# ATtiny20 device description
Architecture: AVR8L; Family: tinyAVR
Registers are 8-bit, access not given, no defined reset value unless marked. A register's access mark holds for its fields unless they carry their own. Offsets are from the block's base; [hi:lo] are bit positions.

## EXINT — External Interrupts
Instances: EXINT 0x00
0x09 PCMSK0 — Pin Change Mask Register 0
  [7:0] PCINT — Pin Change Enable Masks
0x0A PCMSK1 — Pin Change Mask Register 1
  [3:0] PCINT (bit 8 of the value upward) — Pin Change Enable Masks
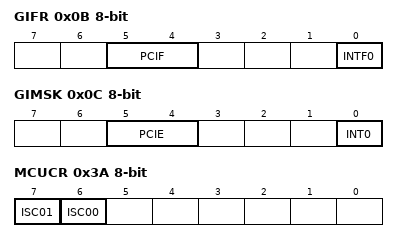
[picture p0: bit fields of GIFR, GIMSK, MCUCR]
0x0B GIFR — General Interrupt Flag Register
  [5:4] PCIF — Pin Change Interrupt Flags
  [0] INTF0 — External Interrupt Flag 0
0x0C GIMSK — General Interrupt Mask Register
  [5:4] PCIE — Pin Change Interrupt Enables
  [0] INT0 — External Interrupt Request 0 Enable
0x3A MCUCR — MCU Control Register
  [7] ISC01 — Interrupt Sense Control 0 Bit 1
  [6] ISC00 — Interrupt Sense Control 0 Bit 0
    0=Low Level of INTX; 1=Any logical change on INTX; 2=Falling Edge of INTX; 3=Rising Edge of INTX

## TC0 (TC8 module) — Timer/Counter, 8-bit
Instances: TC0 0x00
0x15 OCR0B — Timer/Counter0 Output Compare Register
0x16 OCR0A — Timer/Counter0 Output Compare Register
0x17 TCNT0 — Timer/Counter0
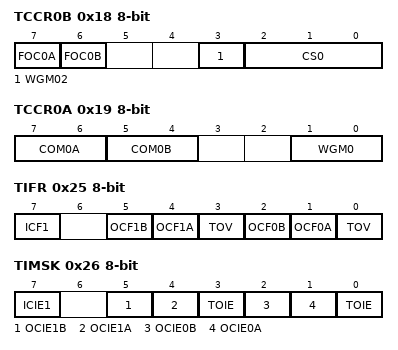
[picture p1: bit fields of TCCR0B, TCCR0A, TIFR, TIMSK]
0x18 TCCR0B — Timer/Counter 0 Control Register B
  [7] FOC0A — Force Output Compare A
  [6] FOC0B — Force Output Compare B
  [3] WGM02 — Waveform Generation Mode
  [2:0] CS0 — Clock Select
    0=No Clock Source (Stopped); 1=Running, No Prescaling; 2=Running, CLK/8; 3=Running, CLK/64; 4=Running, CLK/256; 5=Running, CLK/1024; 6=Running, ExtClk Tx Falling Edge; 7=Running, ExtClk Tx Rising Edge
0x19 TCCR0A — Timer/Counter 0 Control Register A
  [7:6] COM0A — Compare Output Mode for Channel A bits
  [5:4] COM0B — Compare Output Mode for Channel B bits
  [1:0] WGM0 — Waveform Generation Mode
0x25 TIFR — Overflow Interrupt Enable
  [7] ICF1 — Input Capture Flag
  [5] OCF1B — Timer Output Compare Flag 1B
  [4] OCF1A — Timer Output Compare Flag 1A
  [2] OCF0B — Output Compare Flag 0 B
  [1] OCF0A — Output Compare Flag 0 A
  [3,0] TOV — Timer Overflow Flag
0x26 TIMSK — Timer Interrupt Mask Register
  [7] ICIE1 — Input Capture Interrupt Enable
  [5] OCIE1B — Output Compare B Match Interrupt Enable
  [4] OCIE1A — Output Compare A Match Interrupt Enable
  [2] OCIE0B — Timer/Counter Output Compare Match B Interrupt Enable
  [1] OCIE0A — Timer/Counter0 Output Compare Match A Interrupt Enable
  [3,0] TOIE — Overflow Interrupt Enable
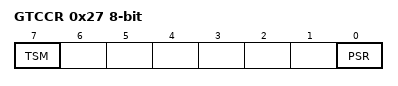
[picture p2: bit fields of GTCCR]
0x27 GTCCR — General Timer/Counter Control Register
  [7] TSM — Timer Synchronization Mode
  [0] PSR — Prescaler Reset

## TWI — Two Wire Serial Interface
Instances: TWI 0x00
0x28 TWSD — TWI Slave Data Register
  [7:0] TWSD — TWI slave data bit
0x29 TWSAM — TWI Slave Address Mask Register
0x2A TWSA — TWI Slave Address Register
  [7:0] TWSA — TWI slave address bit
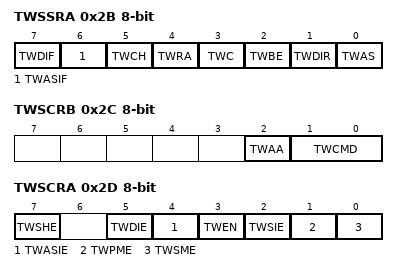
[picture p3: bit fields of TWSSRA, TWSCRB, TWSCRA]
0x2B TWSSRA — TWI Slave Status Register A
  [7] TWDIF — TWI Data Interrupt Flag
  [6] TWASIF — TWI Address/Stop Interrupt Flag
  [5] TWCH — TWI Clock Hold
  [4] TWRA — TWI Receive Acknowledge
  [3] TWC — TWI Collision
  [2] TWBE — TWI Bus Error
  [1] TWDIR — TWI Read/Write Direction
  [0] TWAS — TWI Address or Stop
0x2C TWSCRB — TWI Slave Control Register B
  [2] TWAA — TWI Acknowledge Action
  [1:0] TWCMD
0x2D TWSCRA — TWI Slave Control Register A
  [7] TWSHE — TWI SDA Hold Time Enable
  [5] TWDIE — TWI Data Interrupt Enable
  [4] TWASIE — TWI Address/Stop Interrupt Enable
  [3] TWEN — Two-Wire Interface Enable
  [2] TWSIE — TWI Stop Interrupt Enable
  [1] TWPME — TWI Promiscuous Mode Enable
  [0] TWSME — TWI Smart Mode Enable

## TC1 (TC16 module) — Timer/Counter, 16-bit
Instances: TC1 0x00
0x1A ICR1 16-bit — Input Capture Register Bytes
0x1C OCR1B 16-bit — Timer/Counter1 Output Compare Register B
0x1E OCR1A 16-bit — Timer/Counter 1 Output Compare Register A
0x20 TCNT1 16-bit — Timer/Counter1
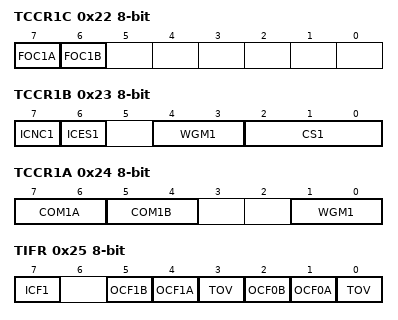
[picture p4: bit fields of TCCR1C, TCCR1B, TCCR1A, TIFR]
0x22 TCCR1C — Timer/Counter1 Control Register C
  [7] FOC1A — Force Output Compare for channel A
  [6] FOC1B — Force Output Compare for channel B
0x23 TCCR1B — Timer/Counter1 Control Register B
  [7] ICNC1 — Input Capture 1 Noise Canceler
  [6] ICES1 — Input Capture 1 Edge Select
  [4:3] WGM1 (bit 2 of the value upward) — Waveform Generation Mode
  [2:0] CS1 — Clock Select1 bits
    0=No Clock Source (Stopped); 1=Running, No Prescaling; 2=Running, CLK/8; 3=Running, CLK/64; 4=Running, CLK/256; 5=Running, CLK/1024; 6=Running, ExtClk Tx Falling Edge; 7=Running, ExtClk Tx Rising Edge
0x24 TCCR1A — Timer/Counter1 Control Register A
  [7:6] COM1A — Compare Output Mode 1A, bits
  [5:4] COM1B — Compare Output Mode 1B, bits
  [1:0] WGM1 — Waveform Generation Mode Bits
0x25 TIFR — Overflow Interrupt Enable
  [7] ICF1 — Input Capture Flag
  [5] OCF1B — Timer Output Compare Flag 1B
  [4] OCF1A — Timer Output Compare Flag 1A
  [2] OCF0B — Output Compare Flag 0 B
  [1] OCF0A — Output Compare Flag 0 A
  [3,0] TOV — Timer Overflow Flag
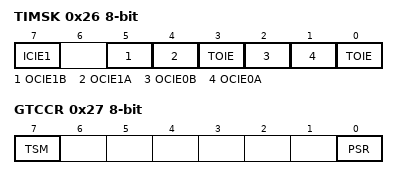
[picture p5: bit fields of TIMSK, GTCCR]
0x26 TIMSK — Timer Interrupt Mask Register
  [7] ICIE1 — Input Capture Interrupt Enable
  [5] OCIE1B — Output Compare B Match Interrupt Enable
  [4] OCIE1A — Output Compare A Match Interrupt Enable
  [2] OCIE0B — Timer/Counter Output Compare Match B Interrupt Enable
  [1] OCIE0A — Timer/Counter0 Output Compare Match A Interrupt Enable
  [3,0] TOIE — Overflow Interrupt Enable
0x27 GTCCR — General Timer/Counter Control Register
  [7] TSM — Timer Synchronization Mode
  [0] PSR — Prescaler Reset

## SPI — Serial Peripheral Interface
Instances: SPI 0x00
0x2E SPDR — SPI Data Register
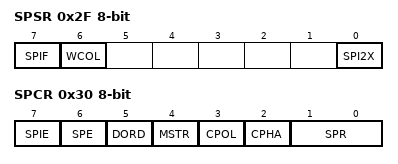
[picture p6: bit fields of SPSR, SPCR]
0x2F SPSR — SPI Status Register
  [7] SPIF — SPI Interrupt Flag
  [6] WCOL — Write Collision Flag
  [0] SPI2X — Double SPI Speed Bit
0x30 SPCR — SPI Control Register
  [7] SPIE — SPI Interrupt Enable
  [6] SPE — SPI Enable
  [5] DORD — Data Order
  [4] MSTR — Master/Slave Select
  [3] CPOL — Clock polarity
  [2] CPHA — Clock Phase
  [1:0] SPR — SPI Clock Rate Selects
    0=fcl/4; 1=fcl/16; 2=fcl/64; 3=fcl/128
